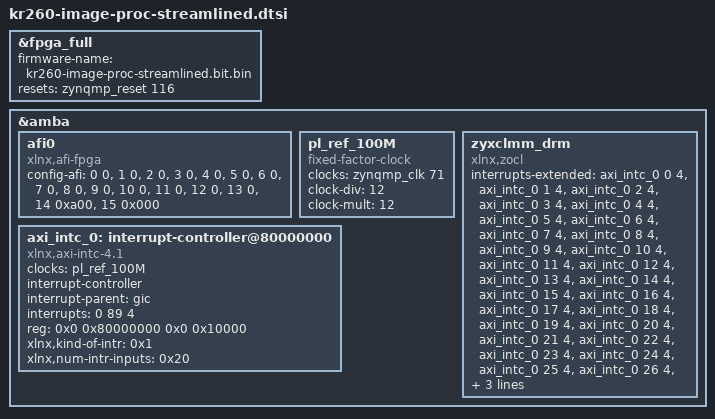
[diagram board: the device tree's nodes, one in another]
// SPDX-License-Identifier: GPL-2.0
/*
 * dts file for Xilinx KR260 motor drives
 *
 * (C) Copyright 2023, Advanced Micro Devices, Inc.
 *
 */

/dts-v1/;
/plugin/;
&fpga_full {
	firmware-name = "kr260-image-proc-streamlined.bit.bin";
	resets = <&zynqmp_reset 116>;
};
&amba {
	#address-cells = <2>;
	#size-cells = <2>;
	afi0: afi0 {
		compatible = "xlnx,afi-fpga";
		config-afi = < 0 0>, <1 0>, <2 0>, <3 0>, <4 0>, <5 0>, <6 0>, <7 0>, <8 0>, <9 0>, <10 0>, <11 0>, <12 0>, <13 0>, <14 0xa00>, <15 0x000>;
	};
	pl_ref_100M: pl_ref_100M {
		#clock-cells = <0x0>;
		compatible = "fixed-factor-clock";
		clocks = <&zynqmp_clk 71>;
		clock-div = <12>;
		clock-mult = <12>;
	};
	axi_intc_0: interrupt-controller@80000000 {
		#interrupt-cells = <2>;
		clock-names = "s_axi_aclk";
		clocks = <&pl_ref_100M>;
		compatible = "xlnx,axi-intc-4.1", "xlnx,xps-intc-1.00.a";
		interrupt-controller ;
		interrupt-names = "irq";
		interrupt-parent = <&gic>;
		interrupts = <0 89 4>;
		reg = <0x0 0x80000000 0x0 0x10000>;
		xlnx,kind-of-intr = <0x1>;
		xlnx,num-intr-inputs = <0x20>;
	};
	zyxclmm_drm {
		compatible = "xlnx,zocl";
		interrupts-extended = <&axi_intc_0 0 4>, <&axi_intc_0 1 4>, <&axi_intc_0 2 4>, <&axi_intc_0 3 4>, <&axi_intc_0 4 4>, <&axi_intc_0 5 4>, <&axi_intc_0 6 4>, <&axi_intc_0 7 4>, <&axi_intc_0 8 4>, <&axi_intc_0 9 4>,
			<&axi_intc_0 10 4>, <&axi_intc_0 11 4>, <&axi_intc_0 12 4>, <&axi_intc_0 13 4>, <&axi_intc_0 14 4>,
			<&axi_intc_0 15 4>, <&axi_intc_0 16 4>, <&axi_intc_0 17 4>, <&axi_intc_0 18 4>, <&axi_intc_0 19 4>,
			<&axi_intc_0 20 4>, <&axi_intc_0 21 4>, <&axi_intc_0 22 4>, <&axi_intc_0 23 4>, <&axi_intc_0 24 4>,
			<&axi_intc_0 25 4>, <&axi_intc_0 26 4>, <&axi_intc_0 27 4>, <&axi_intc_0 28 4>, <&axi_intc_0 29 4>,
			<&axi_intc_0 30 4>, <&axi_intc_0 31 4 >;
	};
};
